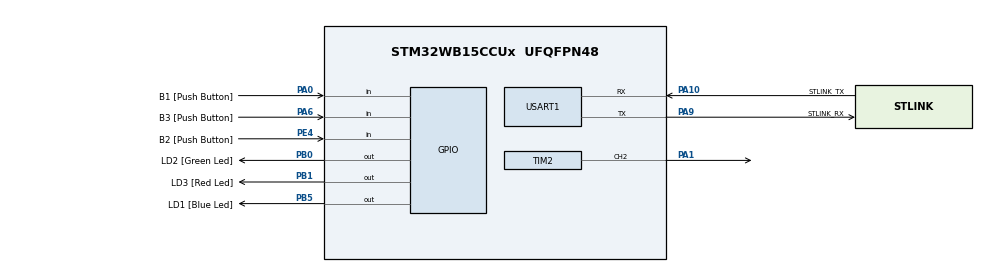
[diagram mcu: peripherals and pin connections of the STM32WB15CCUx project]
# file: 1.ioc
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Mcu.Family=STM32WB
Mcu.Name=STM32WB15CCUx
Mcu.Package=UFQFPN48
NVIC.PriorityGroup=NVIC_PRIORITYGROUP_4
OSC_IN.Mode=HSE-External-Oscillator
OSC_IN.Signal=RCC_OSC_IN
OSC_OUT.Mode=HSE-External-Oscillator
OSC_OUT.Signal=RCC_OSC_OUT
PA0.GPIO_Label=B1 [Push Button]
PA0.Signal=GPIO_Input
PA1.Signal=S_TIM2_CH2
PA10.GPIO_Label=STLINK_TX
PA10.GPIO_PuPd=GPIO_PULLUP
PA10.Mode=Asynchronous
PA10.Signal=USART1_RX
PA13.GPIO_Label=JTMS
PA13.Mode=Serial_Wire
PA13.Signal=SYS_JTMS-SWDIO
PA14.GPIO_Label=JTCK
PA14.Mode=Serial_Wire
PA14.Signal=SYS_JTCK-SWCLK
PA6.GPIO_Label=B3 [Push Button]
PA6.GPIO_PuPd=GPIO_PULLUP
PA6.Signal=GPIO_Input
PA9.GPIO_Label=STLINK_RX
PA9.GPIO_PuPd=GPIO_PULLUP
PA9.Mode=Asynchronous
PA9.Signal=USART1_TX
PB0.GPIO_Label=LD2 [Green Led]
PB0.Signal=GPIO_Output
PB1.GPIO_Label=LD3 [Red Led]
PB1.Signal=GPIO_Output
PB3.GPIO_Label=JTDO
PB3.Signal=SYS_JTDO-SWO
PB5.GPIO_Label=LD1 [Blue Led]
PB5.Signal=GPIO_Output
PC14-OSC32_IN.Mode=LSE-External-Oscillator
PC14-OSC32_IN.Signal=RCC_OSC32_IN
PC15-OSC32_OUT.Mode=LSE-External-Oscillator
PC15-OSC32_OUT.Signal=RCC_OSC32_OUT
PE4.GPIO_Label=B2 [Push Button]
PE4.GPIO_PuPd=GPIO_PULLUP
PE4.Signal=GPIO_Input
ProjectManager.HeapSize=0x200
ProjectManager.StackSize=0x400
ProjectManager.TargetToolchain=MDK-ARM V5.32
RCC.AHB2CLKDivider=RCC_SYSCLK_DIV2
RCC.AHBFreq_Value=64000000
RCC.APB1Freq_Value=64000000
RCC.APB1TimFreq_Value=64000000
RCC.APB2Freq_Value=64000000
RCC.APB2TimFreq_Value=64000000
RCC.APB3Freq_Value=16000000
RCC.CortexFreq_Value=64000000
RCC.HCLKFreq_Value=64000000
RCC.HSE_VALUE=32000000
RCC.HSI_VALUE=16000000
RCC.PLLN=32
RCC.SYSCLKFreq_VALUE=64000000
RCC.SYSCLKSource=RCC_SYSCLKSOURCE_PLLCLK
RCC.VCOOutputFreq_Value=128000000
SH.S_TIM2_CH2.0=TIM2_CH2,PWM Generation2 CH2
TIM2.AutoReloadPreload=TIM_AUTORELOAD_PRELOAD_ENABLE
TIM2.Channel-PWM\ Generation2\ CH2=TIM_CHANNEL_2
TIM2.Period=1999
TIM2.Prescaler=639
USART1.VirtualMode-Asynchronous=VM_ASYNC
VP_TIM2_VS_ClockSourceINT.Mode=Internal
board=NUCLEO-WB15CC

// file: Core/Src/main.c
/* USER CODE BEGIN Header */
/**
  ******************************************************************************
  * @file           : main.c
  * @brief          : Main program body
  ******************************************************************************
  * @attention
  *
  * Copyright (c) 2023 STMicroelectronics.
  * All rights reserved.
  *
  * This software is licensed under terms that can be found in the LICENSE file
  * in the root directory of this software component.
  * If no LICENSE file comes with this software, it is provided AS-IS.
  *
  ******************************************************************************
  */
/* USER CODE END Header */
#include "main.h"
#include "tim.h"
#include "usart.h"
#include "gpio.h"

void SystemClock_Config(void);
void PeriphCommonClock_Config(void);

int main(void)
{

  /* MCU Configuration--------------------------------------------------------*/

  /* Reset of all peripherals, Initializes the Flash interface and the Systick. */
  HAL_Init();

  /* Configure the system clock */
  SystemClock_Config();

/* Configure the peripherals common clocks */
  PeriphCommonClock_Config();

  /* Initialize all configured peripherals */
  MX_GPIO_Init();
  MX_TIM2_Init();
  MX_USART1_UART_Init();
  /* USER CODE BEGIN 2 */
    HAL_TIM_PWM_Start(&htim2,TIM_CHANNEL_2);
  /* USER CODE END 2 */

  /* Infinite loop */
  while (1)
  {

    /* USER CODE BEGIN 3 */
      TIM2->CCR2 = 180;
      HAL_Delay(9000);
      TIM2->CCR2 = 60;
      HAL_Delay(8500);
  }
  /* USER CODE END 3 */
}

void SystemClock_Config(void)
{
  RCC_OscInitTypeDef RCC_OscInitStruct = {0};
  RCC_ClkInitTypeDef RCC_ClkInitStruct = {0};

  /** Configure LSE Drive Capability
  */
  HAL_PWR_EnableBkUpAccess();
  __HAL_RCC_LSEDRIVE_CONFIG(RCC_LSEDRIVE_MEDIUMHIGH);

  /** Initializes the RCC Oscillators according to the specified parameters
  * in the RCC_OscInitTypeDef structure.
  */
  RCC_OscInitStruct.OscillatorType = RCC_OSCILLATORTYPE_HSI|RCC_OSCILLATORTYPE_HSE
                              |RCC_OSCILLATORTYPE_LSE|RCC_OSCILLATORTYPE_MSI;
  RCC_OscInitStruct.HSEState = RCC_HSE_ON;
  RCC_OscInitStruct.LSEState = RCC_LSE_ON;
  RCC_OscInitStruct.HSIState = RCC_HSI_ON;
  RCC_OscInitStruct.MSIState = RCC_MSI_ON;
  RCC_OscInitStruct.HSICalibrationValue = RCC_HSICALIBRATION_DEFAULT;
  RCC_OscInitStruct.MSICalibrationValue = RCC_MSICALIBRATION_DEFAULT;
  RCC_OscInitStruct.MSIClockRange = RCC_MSIRANGE_6;
  RCC_OscInitStruct.PLL.PLLState = RCC_PLL_ON;
  RCC_OscInitStruct.PLL.PLLSource = RCC_PLLSOURCE_MSI;
  RCC_OscInitStruct.PLL.PLLM = RCC_PLLM_DIV1;
  RCC_OscInitStruct.PLL.PLLN = 32;
  RCC_OscInitStruct.PLL.PLLP = RCC_PLLP_DIV2;
  RCC_OscInitStruct.PLL.PLLR = RCC_PLLR_DIV2;
  RCC_OscInitStruct.PLL.PLLQ = RCC_PLLQ_DIV2;
  if (HAL_RCC_OscConfig(&RCC_OscInitStruct) != HAL_OK)
  {
    Error_Handler();
  }

  /** Configure the SYSCLKSource, HCLK, PCLK1 and PCLK2 clocks dividers
  */
  RCC_ClkInitStruct.ClockType = RCC_CLOCKTYPE_HCLK4|RCC_CLOCKTYPE_HCLK2
                              |RCC_CLOCKTYPE_HCLK|RCC_CLOCKTYPE_SYSCLK
                              |RCC_CLOCKTYPE_PCLK1|RCC_CLOCKTYPE_PCLK2;
  RCC_ClkInitStruct.SYSCLKSource = RCC_SYSCLKSOURCE_PLLCLK;
  RCC_ClkInitStruct.AHBCLKDivider = RCC_SYSCLK_DIV1;
  RCC_ClkInitStruct.APB1CLKDivider = RCC_HCLK_DIV1;
  RCC_ClkInitStruct.APB2CLKDivider = RCC_HCLK_DIV1;
  RCC_ClkInitStruct.AHBCLK2Divider = RCC_SYSCLK_DIV2;
  RCC_ClkInitStruct.AHBCLK4Divider = RCC_SYSCLK_DIV1;

  if (HAL_RCC_ClockConfig(&RCC_ClkInitStruct, FLASH_LATENCY_3) != HAL_OK)
  {
    Error_Handler();
  }

  /** Enable MSI Auto calibration
  */
  HAL_RCCEx_EnableMSIPLLMode();
}

void PeriphCommonClock_Config(void)
{
  RCC_PeriphCLKInitTypeDef PeriphClkInitStruct = {0};

  /** Initializes the peripherals clock
  */
  PeriphClkInitStruct.PeriphClockSelection = RCC_PERIPHCLK_SMPS;
  PeriphClkInitStruct.SmpsClockSelection = RCC_SMPSCLKSOURCE_HSI;
  PeriphClkInitStruct.SmpsDivSelection = RCC_SMPSCLKDIV_RANGE1;

  if (HAL_RCCEx_PeriphCLKConfig(&PeriphClkInitStruct) != HAL_OK)
  {
    Error_Handler();
  }
}

void Error_Handler(void)
{
  __disable_irq();
  while (1)
  {
  }
}
